# CY8C5888LTI_LP097 register map
File version: 0.1
Registers are 8-bit, read-write, no defined reset value unless marked. A register's access mark holds for its fields unless they carry their own. Offsets are from the block's base; [hi:lo] are bit positions; 'fields as' and 'values as' point back to an identical list.

## Eyelids
Base 0x00000000
0x40006428 Eyelids_COMPARE_1 16-bit — UDB.D0 - Assigned Compare1 Value
0x40006438 Eyelids_COMPARE_2 16-bit — UDB.D1 - Assigned Compare2 Value
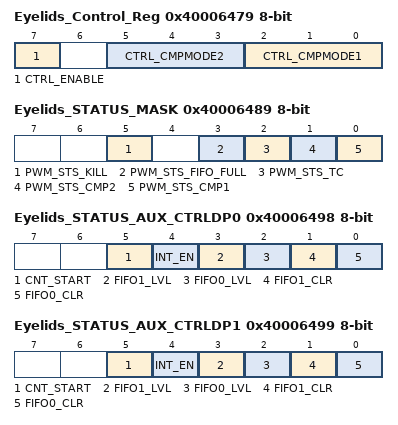
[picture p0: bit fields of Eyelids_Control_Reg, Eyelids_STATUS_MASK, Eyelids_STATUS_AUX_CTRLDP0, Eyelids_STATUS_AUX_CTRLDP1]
0x40006479 Eyelids_Control_Reg — UDB Control Register - Assigned Control Register Value
  [7] CTRL_ENABLE — Enable the PWM
  [5:3] CTRL_CMPMODE2 — Compare mode 2
  [2:0] CTRL_CMPMODE1 — Compare mode 1
0x40006489 Eyelids_STATUS_MASK — UDB Status bits Interrupt Mask Enable Register
  [5] PWM_STS_KILL ro — Enables the Interrupt on Kill
  [3] PWM_STS_FIFO_FULL ro — FIFO Full Status Mask
  [2] PWM_STS_TC ro — Enables the Interrupt on Terminal Count
  [1] PWM_STS_CMP2 ro — Enables the Interrupt on Compare 2
  [0] PWM_STS_CMP1 ro — Enables the Interrupt on Compare 1
0x40006498 Eyelids_STATUS_AUX_CTRLDP0 — UDB Auxilliary Control Register
  [5] CNT_START — FIFO0 clear
    0=E_CNT_START0 (Disable counter); 1=E_CNT_START1 (Enable counter)
  [4] INT_EN
    0=E_INT_EN0 (Interrupt disabled); 1=E_INT_EN1 (Interrupt enabled)
  [3] FIFO1_LVL — FIFO level
    0=E_FIFO_LVL_0 (FIFO LVL: input mode: FIFO not full; output mode: FIFO not empty); 1=E_FIFO_LVL_1 (FIFO LVL: input mode: FIFO at least 1/2 empty; output mode: FIFO at least 1/2 full)
  [2] FIFO0_LVL — FIFO level
    values as FIFO1_LVL
  [1] FIFO1_CLR — FIFO1 clear
    0=E_FIFO_CLR_0 (Normal FIFO operation); 1=E_FIFO_CLR_1 (Clear FIFO state)
  [0] FIFO0_CLR — FIFO0 clear
    values as FIFO1_CLR
0x40006499 Eyelids_STATUS_AUX_CTRLDP1 — UDB Auxilliary Control Register
  fields as Eyelids_STATUS_AUX_CTRLDP0

## Lips
Base 0x00000000
0x40006422 Lips_COMPARE_1 16-bit — UDB.D0 - Assigned Compare1 Value
0x40006432 Lips_COMPARE_2 16-bit — UDB.D1 - Assigned Compare2 Value
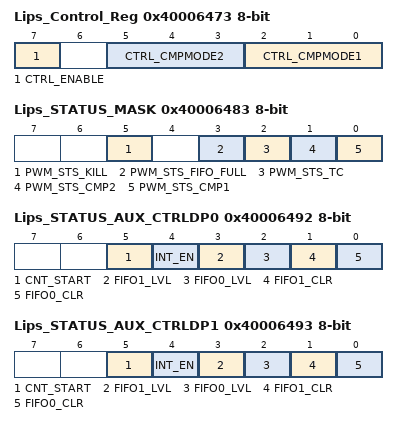
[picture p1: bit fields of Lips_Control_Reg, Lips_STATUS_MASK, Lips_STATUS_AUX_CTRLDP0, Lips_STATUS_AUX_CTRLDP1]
0x40006473 Lips_Control_Reg — UDB Control Register - Assigned Control Register Value
  [7] CTRL_ENABLE — Enable the PWM
  [5:3] CTRL_CMPMODE2 — Compare mode 2
  [2:0] CTRL_CMPMODE1 — Compare mode 1
0x40006483 Lips_STATUS_MASK — UDB Status bits Interrupt Mask Enable Register
  [5] PWM_STS_KILL ro — Enables the Interrupt on Kill
  [3] PWM_STS_FIFO_FULL ro — FIFO Full Status Mask
  [2] PWM_STS_TC ro — Enables the Interrupt on Terminal Count
  [1] PWM_STS_CMP2 ro — Enables the Interrupt on Compare 2
  [0] PWM_STS_CMP1 ro — Enables the Interrupt on Compare 1
0x40006492 Lips_STATUS_AUX_CTRLDP0 — UDB Auxilliary Control Register
  [5] CNT_START — FIFO0 clear
    0=E_CNT_START0 (Disable counter); 1=E_CNT_START1 (Enable counter)
  [4] INT_EN
    0=E_INT_EN0 (Interrupt disabled); 1=E_INT_EN1 (Interrupt enabled)
  [3] FIFO1_LVL — FIFO level
    0=E_FIFO_LVL_0 (FIFO LVL: input mode: FIFO not full; output mode: FIFO not empty); 1=E_FIFO_LVL_1 (FIFO LVL: input mode: FIFO at least 1/2 empty; output mode: FIFO at least 1/2 full)
  [2] FIFO0_LVL — FIFO level
    values as FIFO1_LVL
  [1] FIFO1_CLR — FIFO1 clear
    0=E_FIFO_CLR_0 (Normal FIFO operation); 1=E_FIFO_CLR_1 (Clear FIFO state)
  [0] FIFO0_CLR — FIFO0 clear
    values as FIFO1_CLR
0x40006493 Lips_STATUS_AUX_CTRLDP1 — UDB Auxilliary Control Register
  fields as Lips_STATUS_AUX_CTRLDP0

## RightEyeball
Base 0x00000000
0x4000642E RightEyeball_COMPARE_1 16-bit — UDB.D0 - Assigned Compare1 Value
0x4000643E RightEyeball_COMPARE_2 16-bit — UDB.D1 - Assigned Compare2 Value
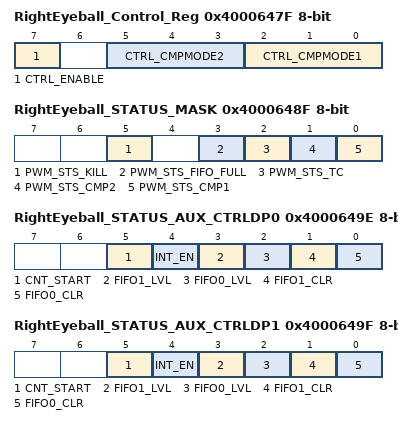
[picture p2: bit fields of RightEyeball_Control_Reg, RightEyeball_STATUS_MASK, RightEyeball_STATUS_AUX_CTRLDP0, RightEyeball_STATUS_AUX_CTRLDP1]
0x4000647F RightEyeball_Control_Reg — UDB Control Register - Assigned Control Register Value
  [7] CTRL_ENABLE — Enable the PWM
  [5:3] CTRL_CMPMODE2 — Compare mode 2
  [2:0] CTRL_CMPMODE1 — Compare mode 1
0x4000648F RightEyeball_STATUS_MASK — UDB Status bits Interrupt Mask Enable Register
  [5] PWM_STS_KILL ro — Enables the Interrupt on Kill
  [3] PWM_STS_FIFO_FULL ro — FIFO Full Status Mask
  [2] PWM_STS_TC ro — Enables the Interrupt on Terminal Count
  [1] PWM_STS_CMP2 ro — Enables the Interrupt on Compare 2
  [0] PWM_STS_CMP1 ro — Enables the Interrupt on Compare 1
0x4000649E RightEyeball_STATUS_AUX_CTRLDP0 — UDB Auxilliary Control Register
  [5] CNT_START — FIFO0 clear
    0=E_CNT_START0 (Disable counter); 1=E_CNT_START1 (Enable counter)
  [4] INT_EN
    0=E_INT_EN0 (Interrupt disabled); 1=E_INT_EN1 (Interrupt enabled)
  [3] FIFO1_LVL — FIFO level
    0=E_FIFO_LVL_0 (FIFO LVL: input mode: FIFO not full; output mode: FIFO not empty); 1=E_FIFO_LVL_1 (FIFO LVL: input mode: FIFO at least 1/2 empty; output mode: FIFO at least 1/2 full)
  [2] FIFO0_LVL — FIFO level
    values as FIFO1_LVL
  [1] FIFO1_CLR — FIFO1 clear
    0=E_FIFO_CLR_0 (Normal FIFO operation); 1=E_FIFO_CLR_1 (Clear FIFO state)
  [0] FIFO0_CLR — FIFO0 clear
    values as FIFO1_CLR
0x4000649F RightEyeball_STATUS_AUX_CTRLDP1 — UDB Auxilliary Control Register
  fields as RightEyeball_STATUS_AUX_CTRLDP0
